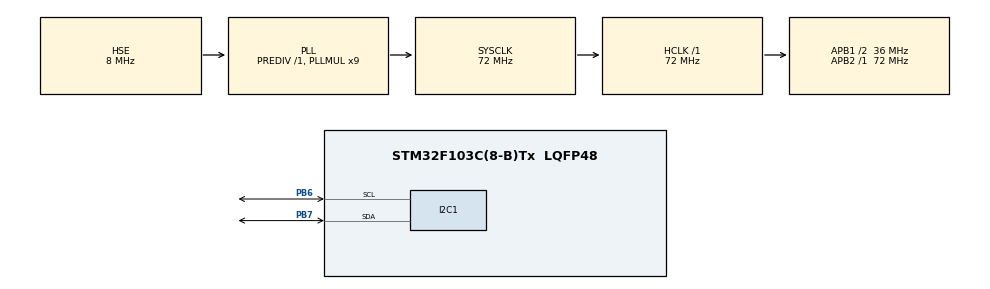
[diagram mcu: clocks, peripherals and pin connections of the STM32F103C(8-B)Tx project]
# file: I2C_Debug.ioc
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Mcu.Family=STM32F1
Mcu.Name=STM32F103C(8-B)Tx
Mcu.Package=LQFP48
NVIC.PriorityGroup=NVIC_PRIORITYGROUP_4
PA13.Mode=Serial_Wire
PA13.Signal=SYS_JTMS-SWDIO
PA14.Mode=Serial_Wire
PA14.Signal=SYS_JTCK-SWCLK
PB6.Mode=I2C
PB6.Signal=I2C1_SCL
PB7.Mode=I2C
PB7.Signal=I2C1_SDA
PD0-OSC_IN.Mode=HSE-External-Oscillator
PD0-OSC_IN.Signal=RCC_OSC_IN
PD1-OSC_OUT.Mode=HSE-External-Oscillator
PD1-OSC_OUT.Signal=RCC_OSC_OUT
ProjectManager.HeapSize=0x200
ProjectManager.StackSize=0x400
ProjectManager.TargetToolchain=MDK-ARM V5.32
RCC.AHBFreq_Value=72000000
RCC.APB1CLKDivider=RCC_HCLK_DIV2
RCC.APB1Freq_Value=36000000
RCC.APB1TimFreq_Value=72000000
RCC.APB2Freq_Value=72000000
RCC.APB2TimFreq_Value=72000000
RCC.HCLKFreq_Value=72000000
RCC.PLLMUL=RCC_PLL_MUL9
RCC.PLLSourceVirtual=RCC_PLLSOURCE_HSE
RCC.SYSCLKFreq_VALUE=72000000
RCC.SYSCLKSource=RCC_SYSCLKSOURCE_PLLCLK
RCC.USBFreq_Value=72000000
board=custom

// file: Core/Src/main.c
/* USER CODE BEGIN Header */
/**
  ******************************************************************************
  * @file           : main.c
  * @brief          : Main program body
  ******************************************************************************
  * @attention
  *
  * Copyright (c) 2026 STMicroelectronics.
  * All rights reserved.
  *
  * This software is licensed under terms that can be found in the LICENSE file
  * in the root directory of this software component.
  * If no LICENSE file comes with this software, it is provided AS-IS.
  *
  ******************************************************************************
  */
/* USER CODE END Header */
#include "main.h"
#include "i2c.h"
#include "gpio.h"

/* USER CODE BEGIN PV */
HAL_StatusTypeDef status;
uint8_t whoami;
HAL_StatusTypeDef who_status;
uint32_t who_error;
/* USER CODE END PV */

void SystemClock_Config(void);

int main(void)
{

  /* MCU Configuration--------------------------------------------------------*/

  /* Reset of all peripherals, Initializes the Flash interface and the Systick. */
  HAL_Init();

  /* Configure the system clock */
  SystemClock_Config();

  /* Initialize all configured peripherals */
  MX_GPIO_Init();
  MX_I2C1_Init();
  /* USER CODE BEGIN 2 */

	/*检测I2C总线上地址为0xD0的设备是否在线
	 *0xD0是MOU6050的7位地址0x68左移1位+0（写）的HAL格式地址
	 *最多尝试3次，每次超时100ms
	 *返回HAL_OK表示设备应答，否则未应答、总线忙或超时 */
	status = HAL_I2C_IsDeviceReady(
		&hi2c1,	//I2C1的句柄
    0xD0,	//设备地址0x68<<1+0
    3,	//尝试次数
    100);	//超时时间

	/*向从机的指定寄存器读数据，读取MPU6050的WHO_AM_I身份识别寄存器，判断通信的是不是MPU6050
		 *0xD0是MOU6050的7位地址0x68左移1位+0（写）的HAL格式地址
		 *0X75是WHO_AM_I寄存器地址
		 *I2C_MEMADD_SIZE_8BIT是MPU6050 寄存器地址是 8 位
		 *pData数据缓冲区
		 *读取的字节数,1字节
		 *超时时间100ms */
		who_status = HAL_I2C_Mem_Read(&hi2c1, 0xD0, 0x75, I2C_MEMADD_SIZE_8BIT, &whoami, 1, 100);

		who_error = hi2c1.ErrorCode;
  /* USER CODE END 2 */

  /* Infinite loop */
  while (1)
  {

  }
}

void SystemClock_Config(void)
{
  RCC_OscInitTypeDef RCC_OscInitStruct = {0};
  RCC_ClkInitTypeDef RCC_ClkInitStruct = {0};

  /** Initializes the RCC Oscillators according to the specified parameters
  * in the RCC_OscInitTypeDef structure.
  */
  RCC_OscInitStruct.OscillatorType = RCC_OSCILLATORTYPE_HSE;
  RCC_OscInitStruct.HSEState = RCC_HSE_ON;
  RCC_OscInitStruct.HSEPredivValue = RCC_HSE_PREDIV_DIV1;
  RCC_OscInitStruct.HSIState = RCC_HSI_ON;
  RCC_OscInitStruct.PLL.PLLState = RCC_PLL_ON;
  RCC_OscInitStruct.PLL.PLLSource = RCC_PLLSOURCE_HSE;
  RCC_OscInitStruct.PLL.PLLMUL = RCC_PLL_MUL9;
  if (HAL_RCC_OscConfig(&RCC_OscInitStruct) != HAL_OK)
  {
    Error_Handler();
  }

  /** Initializes the CPU, AHB and APB buses clocks
  */
  RCC_ClkInitStruct.ClockType = RCC_CLOCKTYPE_HCLK|RCC_CLOCKTYPE_SYSCLK
                              |RCC_CLOCKTYPE_PCLK1|RCC_CLOCKTYPE_PCLK2;
  RCC_ClkInitStruct.SYSCLKSource = RCC_SYSCLKSOURCE_PLLCLK;
  RCC_ClkInitStruct.AHBCLKDivider = RCC_SYSCLK_DIV1;
  RCC_ClkInitStruct.APB1CLKDivider = RCC_HCLK_DIV2;
  RCC_ClkInitStruct.APB2CLKDivider = RCC_HCLK_DIV1;

  if (HAL_RCC_ClockConfig(&RCC_ClkInitStruct, FLASH_LATENCY_2) != HAL_OK)
  {
    Error_Handler();
  }
}

void Error_Handler(void)
{
  __disable_irq();
  while (1)
  {
  }
}
